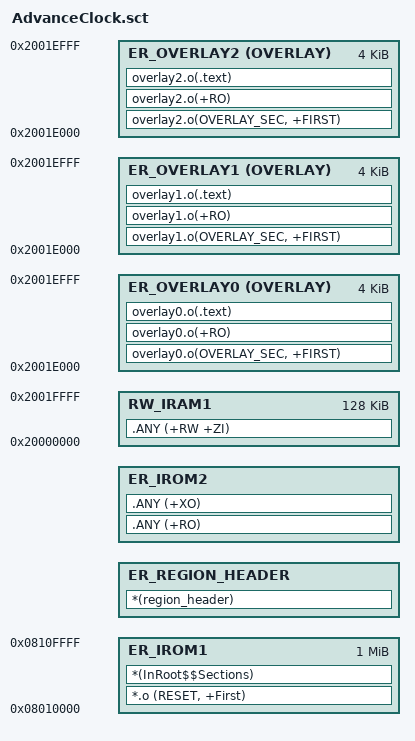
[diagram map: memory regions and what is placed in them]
; *************************************************************
; *** Scatter-Loading Description File generated by uVision ***
; *************************************************************

LR_IROM1 0x08010000 0x00100000  ; load region size_region
{    
  ER_IROM1 0x08010000 0x00100000   ; load address = execution address
  { 
   *.o (RESET, +First)
   *(InRoot$$Sections)
  }
  ER_REGION_HEADER +0
  {
    *(region_header)
  }
  ER_IROM2 +0
  {
    .ANY (+RO)
    .ANY (+XO)
  }
  RW_IRAM1 0x20000000 0x00020000  ; RW data
  {  
   .ANY (+RW +ZI)
  }
}

LR_OVERLAY0 0x30000000  0x1000
{
  ER_OVERLAY0 0x2001E000 OVERLAY   0x1000 
  { 
    overlay0.o(OVERLAY_SEC, +FIRST)
    overlay0.o(+RO)
    overlay0.o(.text)
  }
}

LR_OVERLAY1 0x30001000  0x1000
{
  ER_OVERLAY1 0x2001E000 OVERLAY  0x1000 
  {
    overlay1.o(OVERLAY_SEC, +FIRST)
    overlay1.o(+RO)
    overlay1.o(.text)
  }
}

LR_OVERLAY2 0x30002000  0x1000
{
  ER_OVERLAY2 0x2001E000 OVERLAY  0x1000 
  {
    overlay2.o(OVERLAY_SEC, +FIRST)
    overlay2.o(+RO)
    overlay2.o(.text)
  }
}

